# sifive_hifive_unmatched_a00 register map
Vendor: sifive; File version: 0.1
Registers are 32-bit, read-write, no defined reset value unless marked. A register's access mark holds for its fields unless they carry their own. Offsets are from the block's base; [hi:lo] are bit positions; {n}, {i} and the like mark numbered series.

## riscv_plic0_0 — From riscv,plic0,control peripheral generator
Base 0x0C000000
{0x0+4i} priority_{i} (i=1..69) — PRIORITY Register for interrupt id {i}
0x1000 pending_0 — PENDING Register for interrupt ids 31 to 0
0x1004 pending_1 — PENDING Register for interrupt ids 63 to 32
0x1008 pending_2 — PENDING Register for interrupt ids 69 to 64
{0x2000+0x80*i} enable_0_{i} (i=0..4) — ENABLE Register for interrupt ids 31 to 0 for hart {i}
{0x2004+0x80*i} enable_1_{i} (i=0..4) — ENABLE Register for interrupt ids 63 to 32 for hart {i}
{0x2008+0x80*i} enable_2_{i} (i=0..4) — ENABLE Register for interrupt ids 69 to 64 for hart {i}
{0x200000+0x1000*i} threshold_{i} (i=0..4) — PRIORITY THRESHOLD Register for hart {i}
{0x200004+0x1000*i} claimplete_{i} (i=0..4) — CLAIM and COMPLETE Register for hart {i}

## sifive_pwm0_0 — From sifive,pwm0,control peripheral generator
Base 0x10020000
Same registers: sifive_pwm0_1 0x10021000
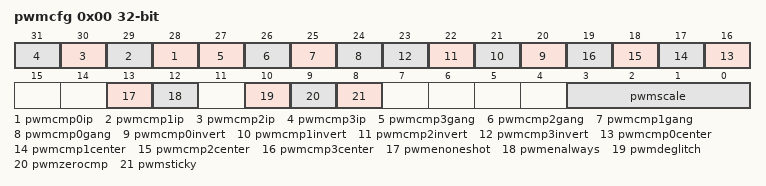
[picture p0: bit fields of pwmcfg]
0x00 pwmcfg — PWM configuration register
  [n+28] pwmcmp{n}ip (n=0..3) — PWM{n} Interrupt Pending
  [27] pwmcmp3gang — PWM3/PWM0 Compare Gang
  [26] pwmcmp2gang — PWM2/PWM3 Compare Gang
  [25] pwmcmp1gang — PWM1/PWM2 Compare Gang
  [24] pwmcmp0gang — PWM0/PWM1 Compare Gang
  [n+20] pwmcmp{n}invert (n=0..3) — PWM{n} Invert
  [n+16] pwmcmp{n}center (n=0..3) — PWM{n} Compare Center
  [13] pwmenoneshot — PWM enable one shot - run one cycle
  [12] pwmenalways — PWM enable always - run continuously
  [10] pwmdeglitch — PWM Deglitch - latch pwmcmpXip within same cycle
  [9] pwmzerocmp — PWM Zero - counter resets to zero after match
  [8] pwmsticky — PWM Sticky - disallow clearing pwmcmpXip bits
  [3:0] pwmscale — PWM Counter scale
0x08 pwmcount
  [30:0] pwmcount
0x10 pwms — Scaled PWM count register
  [15:0] pwms — Scaled PWM count register.
{0x20+4i} pwmcmp{i} (i=0..3) — PWM {i} compare register
  [15:0] pwmcmp{i} — PWM {i} Compare Value

## sifive_uart0_0 — From sifive,uart0,control peripheral generator
Base 0x10010000
Same registers: sifive_uart0_1 0x10011000
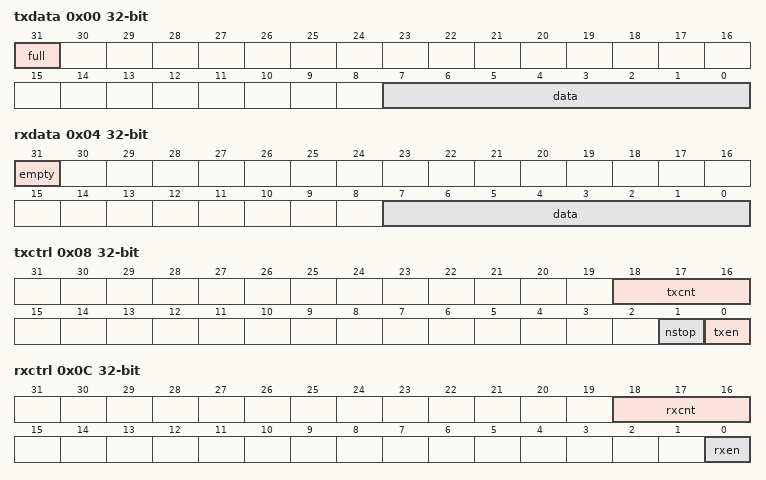
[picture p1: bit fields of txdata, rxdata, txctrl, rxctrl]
0x00 txdata — Transmit data register
  [31] full ro — Transmit FIFO full
  [7:0] data — Transmit data
0x04 rxdata — Receive data register
  [31] empty ro — Receive FIFO empty
  [7:0] data ro — Received data
0x08 txctrl — Transmit control register
  [18:16] txcnt — Transmit watermark level
  [1] nstop — Number of stop bits
  [0] txen — Transmit enable
0x0C rxctrl — Receive control register
  [18:16] rxcnt — Receive watermark level
  [0] rxen — Receive enable
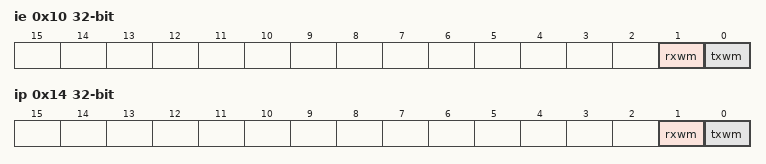
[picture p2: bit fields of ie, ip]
0x10 ie — UART interrupt enable
  [1] rxwm — Receive watermark interrupt enable
  [0] txwm — Transmit watermark interrupt enable
0x14 ip — UART interrupt pending
  [1] rxwm ro — Receive watermark interrupt pending
  [0] txwm ro — Transmit watermark interrupt pending
0x18 div — Baud rate divisor
  [15:0] div — Baud rate divisor.

## sifive_spi0_0 — From sifive,spi0,control peripheral generator
Base 0x10040000
Same registers: sifive_spi0_1 0x10041000, sifive_spi0_2 0x10050000
0x00 sckdiv — Serial clock divisor
  [11:0] div — Divisor for serial clock.
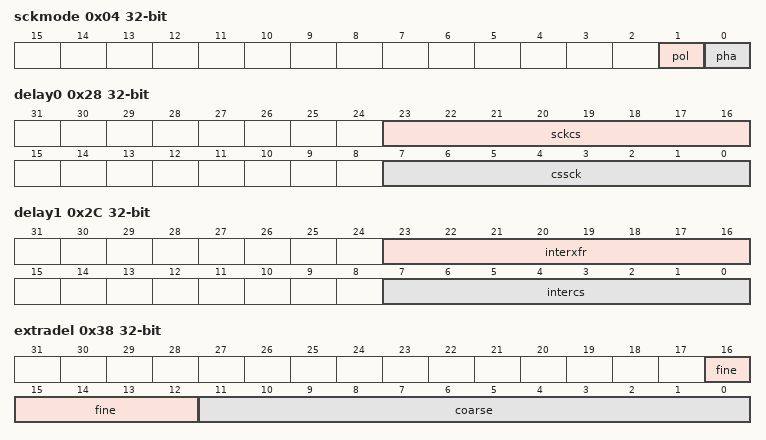
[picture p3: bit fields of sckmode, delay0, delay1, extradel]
0x04 sckmode — Serial clock mode
  [1] pol — Serial clock polarity
  [0] pha — Serial clock phase
0x10 csid — Chip select ID
  [31:0] csid — Chip select ID.
0x14 csdef — Chip select default
  [31:0] csdef — Chip select default value. Reset to all-1s.
0x18 csmode — Chip select mode
  [1:0] mode
0x28 delay0 — Delay control 0
  [23:16] sckcs — SCK to CS Delay
  [7:0] cssck — CS to SCK Delay
0x2C delay1 — Delay control 1
  [23:16] interxfr — Maximum interframe delay
  [7:0] intercs — Minimum CS inactive time
0x38 extradel — SPI extra sampling delay to increase the SPI frequency
  [16:12] fine — Fine grain sample delay (multiples of process-specific buffer delay)
  [11:0] coarse — Coarse grain sample delay (multiples of system clocks)
0x3C sampledel — Number of delay stages from slave to the SPI controller
  [4:0] sd — Number of delay stages from slave to SPI controller
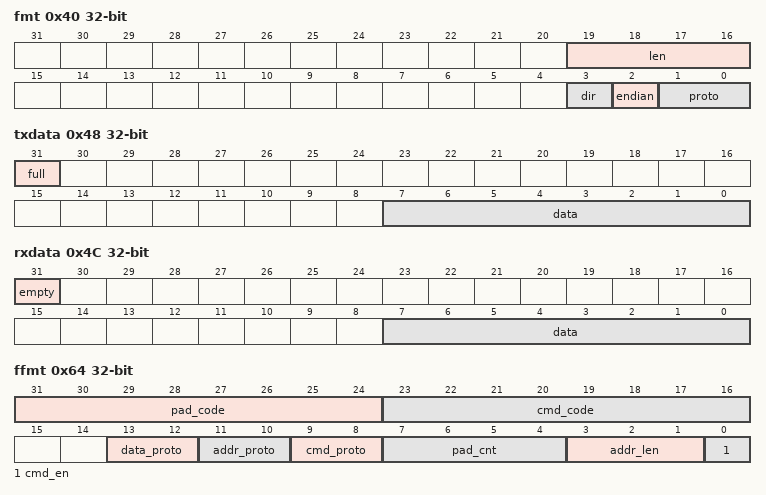
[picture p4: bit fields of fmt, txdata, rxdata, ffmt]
0x40 fmt — Frame format
  [19:16] len — Number of bits per frame
  [3] dir — SPI I/O direction. This is reset to 1 for flash-enabled SPI controllers, 0 otherwise.
  [2] endian — SPI endianness
  [1:0] proto — SPI protocol
0x48 txdata — Tx FIFO Data
  [31] full ro — FIFO full flag
  [7:0] data — Transmit data
0x4C rxdata — Rx FIFO data
  [31] empty — FIFO empty flag
  [7:0] data ro — Received data
0x50 txmark — Tx FIFO watermark
  [2:0] txmark — Transmit watermark. The reset value is 1 for flash-enabled controllers, 0 otherwise.
0x54 rxmark — Rx FIFO watermark
  [2:0] rxmark — Receive watermark
0x60 fctrl — SPI flash interface control
  [0] en — SPI Flash Mode Select
0x64 ffmt — SPI flash instruction format
  [31:24] pad_code — First 8 bits to transmit during dummy cycles
  [23:16] cmd_code — Value of command byte
  [13:12] data_proto — Protocol for receiving data bytes
  [11:10] addr_proto — Protocol for transmitting address and padding
  [9:8] cmd_proto — Protocol for transmitting command
  [7:4] pad_cnt — Number of dummy cycles
  [3:1] addr_len — Number of address bytes (0 to 4)
  [0] cmd_en — Enable sending of command
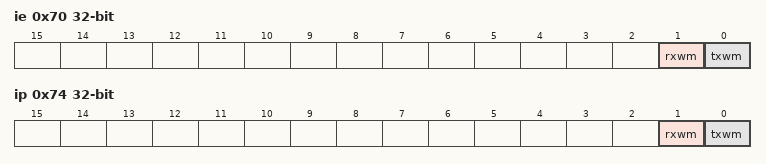
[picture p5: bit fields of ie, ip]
0x70 ie — SPI interrupt enable
  [1] rxwm — Receive watermark enable
  [0] txwm — Transmit watermark enable
0x74 ip — SPI interrupt pending
  [1] rxwm ro — Receive watermark pending
  [0] txwm ro — Transmit watermark pending

## sifive_test0_0 — From sifive,test0,control peripheral generator
Base 0x00004000
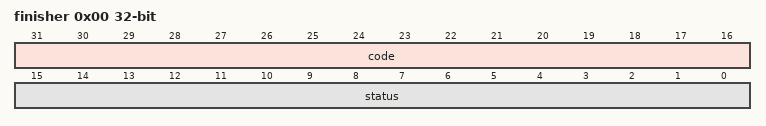
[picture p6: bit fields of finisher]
0x00 finisher — Test finisher register
  [31:16] code — Finisher code
  [15:0] status — Test status
